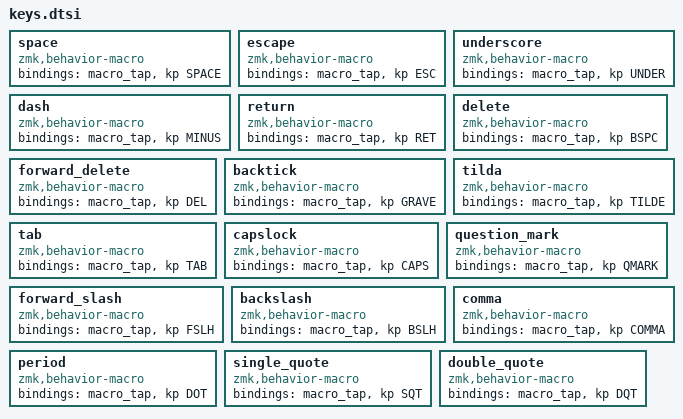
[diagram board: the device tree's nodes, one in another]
space: space {
    compatible = "zmk,behavior-macro";
    #binding-cells = <0>;
    bindings = <&macro_tap &kp SPACE>;
};

escape: escape {
    compatible = "zmk,behavior-macro";
    #binding-cells = <0>;
    bindings = <&macro_tap &kp ESC>;
};

underscore: underscore {
    compatible = "zmk,behavior-macro";
    #binding-cells = <0>;
    bindings = <&macro_tap &kp UNDER>;
};

dash: dash {
    compatible = "zmk,behavior-macro";
    #binding-cells = <0>;
    bindings = <&macro_tap &kp MINUS>;
};

return: return {
    compatible = "zmk,behavior-macro";
    #binding-cells = <0>;
    bindings = <&macro_tap &kp RET>;
};

delete: delete {
    compatible = "zmk,behavior-macro";
    #binding-cells = <0>;
    bindings = <&macro_tap &kp BSPC>;
};

forward_delete: forward_delete {
    compatible = "zmk,behavior-macro";
    #binding-cells = <0>;
    bindings = <&macro_tap &kp DEL>;
};

backtick: backtick {
    compatible = "zmk,behavior-macro";
    #binding-cells = <0>;
    bindings = <&macro_tap &kp GRAVE>;
};

tilda: tilda {
    compatible = "zmk,behavior-macro";
    #binding-cells = <0>;
    bindings = <&macro_tap &kp TILDE>;
};

tab: tab {
    compatible = "zmk,behavior-macro";
    #binding-cells = <0>;
    bindings = <&macro_tap &kp TAB>;
};

capslock: capslock {
    compatible = "zmk,behavior-macro";
    #binding-cells = <0>;
    bindings = <&macro_tap &kp CAPS>;
};

question_mark: question_mark {
    compatible = "zmk,behavior-macro";
    #binding-cells = <0>;
    bindings = <&macro_tap &kp QMARK>;
};

forward_slash: forward_slash {
    compatible = "zmk,behavior-macro";
    #binding-cells = <0>;
    bindings = <&macro_tap &kp FSLH>;
};

backslash: backslash {
    compatible = "zmk,behavior-macro";
    #binding-cells = <0>;
    bindings = <&macro_tap &kp BSLH>;
};

comma: comma {
    compatible = "zmk,behavior-macro";
    #binding-cells = <0>;
    bindings = <&macro_tap &kp COMMA>;
};

period: period {
    compatible = "zmk,behavior-macro";
    #binding-cells = <0>;
    bindings = <&macro_tap &kp DOT>;
};

single_quote: single_quote {
    compatible = "zmk,behavior-macro";
    #binding-cells = <0>;
    bindings = <&macro_tap &kp SQT>;
};

double_quote: double_quote {
    compatible = "zmk,behavior-macro";
    #binding-cells = <0>;
    bindings = <&macro_tap &kp DQT>;
};
